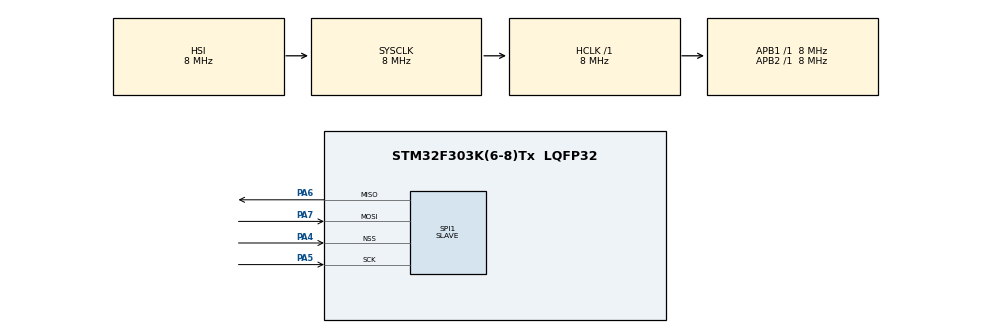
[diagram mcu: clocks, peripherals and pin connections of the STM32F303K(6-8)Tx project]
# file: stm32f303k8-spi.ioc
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Mcu.Family=STM32F3
Mcu.Name=STM32F303K(6-8)Tx
Mcu.Package=LQFP32
NVIC.PriorityGroup=NVIC_PRIORITYGROUP_4
NVIC.SPI1_IRQn=true\:0\:0\:false\:false\:true\:true\:true\:true
PA4.Mode=NSS_Signal_Hard_Input
PA4.Signal=SPI1_NSS
PA5.Mode=Full_Duplex_Slave
PA5.Signal=SPI1_SCK
PA6.Mode=Full_Duplex_Slave
PA6.Signal=SPI1_MISO
PA7.Mode=Full_Duplex_Slave
PA7.Signal=SPI1_MOSI
ProjectManager.HeapSize=0x200
ProjectManager.StackSize=0x400
ProjectManager.TargetToolchain=STM32CubeIDE
RCC.AHBFreq_Value=8000000
RCC.APB1Freq_Value=8000000
RCC.APB2Freq_Value=8000000
RCC.CortexFreq_Value=8000000
RCC.HSE_VALUE=8000000
RCC.HSI_VALUE=8000000
RCC.SYSCLKFreq_VALUE=8000000
SPI1.DataSize=SPI_DATASIZE_8BIT
SPI1.Direction=SPI_DIRECTION_2LINES
SPI1.Mode=SPI_MODE_SLAVE
SPI1.VirtualNSS=VM_NSSHARD
SPI1.VirtualType=VM_SLAVE
board=custom

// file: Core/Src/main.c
/* USER CODE BEGIN Header */
/**
  ******************************************************************************
  * @file           : main.c
  * @brief          : Main program body
  ******************************************************************************
  * @attention
  *
  * Copyright (c) 2026 STMicroelectronics.
  * All rights reserved.
  *
  * This software is licensed under terms that can be found in the LICENSE file
  * in the root directory of this software component.
  * If no LICENSE file comes with this software, it is provided AS-IS.
  *
  ******************************************************************************
  */
/* USER CODE END Header */
#include "main.h"

SPI_HandleTypeDef hspi1;

void SystemClock_Config(void);
static void MX_GPIO_Init(void);
static void MX_SPI1_Init(void);

/* USER CODE BEGIN 0 */

uint8_t rxData[8];
uint8_t txData[] = "response";

void HAL_SPI_TxCpltCallback(SPI_HandleTypeDef *hspi)
{
    if (hspi->Instance == SPI1)
    {
        // Transfer complete, handle the data received and send a response
        HAL_SPI_Receive_IT(hspi, rxData, sizeof(rxData));
    }
}

void HAL_SPI_RxCpltCallback(SPI_HandleTypeDef *hspi)
{
    if (hspi->Instance == SPI1)
    {
        // Data received, handle it and send a response
        HAL_SPI_Transmit_IT(hspi, txData, sizeof(txData));
    }
}

/* USER CODE END 0 */

int main(void)
{

  /* MCU Configuration--------------------------------------------------------*/

  /* Reset of all peripherals, Initializes the Flash interface and the Systick. */
  HAL_Init();

  /* Configure the system clock */
  SystemClock_Config();

  /* Initialize all configured peripherals */
  MX_GPIO_Init();
  MX_SPI1_Init();
  /* USER CODE BEGIN 2 */

    // Enable SPI interrupt-driven slave mode
    HAL_SPI_Receive_IT(&hspi1, rxData, sizeof(rxData));

  /* USER CODE END 2 */

  /* Infinite loop */
  while (1)
  {

  }
}

void SystemClock_Config(void)
{
  RCC_OscInitTypeDef RCC_OscInitStruct = {0};
  RCC_ClkInitTypeDef RCC_ClkInitStruct = {0};

  /** Initializes the RCC Oscillators according to the specified parameters
  * in the RCC_OscInitTypeDef structure.
  */
  RCC_OscInitStruct.OscillatorType = RCC_OSCILLATORTYPE_HSI;
  RCC_OscInitStruct.HSIState = RCC_HSI_ON;
  RCC_OscInitStruct.HSICalibrationValue = RCC_HSICALIBRATION_DEFAULT;
  RCC_OscInitStruct.PLL.PLLState = RCC_PLL_NONE;
  if (HAL_RCC_OscConfig(&RCC_OscInitStruct) != HAL_OK)
  {
    Error_Handler();
  }

  /** Initializes the CPU, AHB and APB buses clocks
  */
  RCC_ClkInitStruct.ClockType = RCC_CLOCKTYPE_HCLK|RCC_CLOCKTYPE_SYSCLK
                              |RCC_CLOCKTYPE_PCLK1|RCC_CLOCKTYPE_PCLK2;
  RCC_ClkInitStruct.SYSCLKSource = RCC_SYSCLKSOURCE_HSI;
  RCC_ClkInitStruct.AHBCLKDivider = RCC_SYSCLK_DIV1;
  RCC_ClkInitStruct.APB1CLKDivider = RCC_HCLK_DIV1;
  RCC_ClkInitStruct.APB2CLKDivider = RCC_HCLK_DIV1;

  if (HAL_RCC_ClockConfig(&RCC_ClkInitStruct, FLASH_LATENCY_0) != HAL_OK)
  {
    Error_Handler();
  }
}

static void MX_SPI1_Init(void)
{

  /* SPI1 parameter configuration*/
  hspi1.Instance = SPI1;
  hspi1.Init.Mode = SPI_MODE_SLAVE;
  hspi1.Init.Direction = SPI_DIRECTION_2LINES;
  hspi1.Init.DataSize = SPI_DATASIZE_8BIT;
  hspi1.Init.CLKPolarity = SPI_POLARITY_LOW;
  hspi1.Init.CLKPhase = SPI_PHASE_1EDGE;
  hspi1.Init.NSS = SPI_NSS_HARD_INPUT;
  hspi1.Init.FirstBit = SPI_FIRSTBIT_MSB;
  hspi1.Init.TIMode = SPI_TIMODE_DISABLE;
  hspi1.Init.CRCCalculation = SPI_CRCCALCULATION_DISABLE;
  hspi1.Init.CRCPolynomial = 7;
  hspi1.Init.CRCLength = SPI_CRC_LENGTH_DATASIZE;
  hspi1.Init.NSSPMode = SPI_NSS_PULSE_DISABLE;
  if (HAL_SPI_Init(&hspi1) != HAL_OK)
  {
    Error_Handler();
  }

}

static void MX_GPIO_Init(void)
{

  /* GPIO Ports Clock Enable */
  __HAL_RCC_GPIOA_CLK_ENABLE();

}

void Error_Handler(void)
{
  __disable_irq();
  while (1)
  {
  }
}
